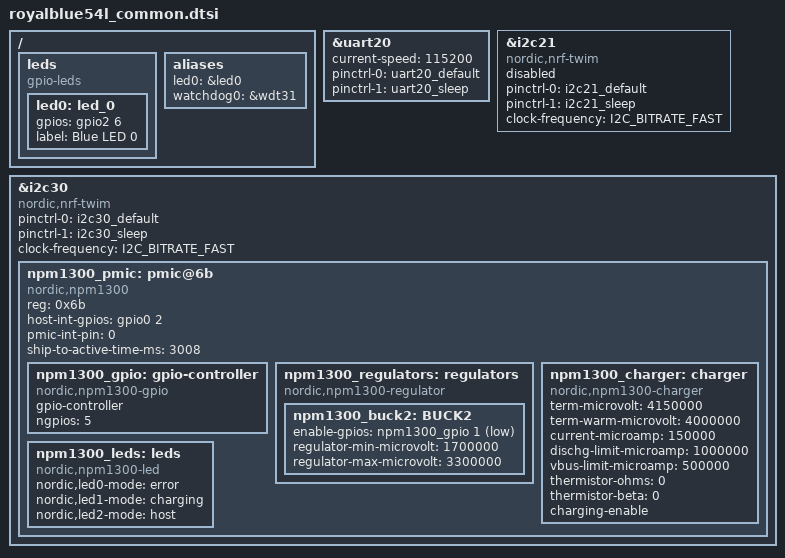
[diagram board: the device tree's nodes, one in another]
/*
 * Copyright (c) 2024 Nordic Semiconductor ASA
 *
 * SPDX-License-Identifier: Apache-2.0
 */

#include "royalblue54l_nrf54l15-pinctrl.dtsi"

/ {
	leds {
		compatible = "gpio-leds";
		led0: led_0 {
			gpios = <&gpio2 6 GPIO_ACTIVE_HIGH>;
			label = "Blue LED 0";
		};
	};

	aliases {
		led0 = &led0;
		watchdog0 = &wdt31;
	};
};

&uart20 {
	current-speed = <115200>;
	pinctrl-0 = <&uart20_default>;
	pinctrl-1 = <&uart20_sleep>;
	pinctrl-names = "default", "sleep";
};

&i2c21 {
	compatible = "nordic,nrf-twim";
	status = "disabled";
	pinctrl-0 = <&i2c21_default>;
	pinctrl-1 = <&i2c21_sleep>;
	pinctrl-names = "default", "sleep";
	clock-frequency = <I2C_BITRATE_FAST>;
};

&i2c30 {
	compatible = "nordic,nrf-twim";
	status = "okay";
	pinctrl-0 = <&i2c30_default>;
	pinctrl-1 = <&i2c30_sleep>;
	pinctrl-names = "default", "sleep";
	clock-frequency = <I2C_BITRATE_FAST>;

	npm1300_pmic: pmic@6b {
		compatible = "nordic,npm1300";
		reg = <0x6b>;
		host-int-gpios = <&gpio0 2 GPIO_ACTIVE_HIGH>;
		pmic-int-pin = <0>;
		ship-to-active-time-ms = <3008>;

		npm1300_gpio: gpio-controller {
			compatible = "nordic,npm1300-gpio";
			gpio-controller;
			#gpio-cells = <2>;
			ngpios = <5>;
		};

		npm1300_regulators: regulators {
			compatible = "nordic,npm1300-regulator";
			npm1300_buck2: BUCK2 {
				enable-gpios = <&npm1300_gpio 1 GPIO_ACTIVE_LOW>;
				regulator-min-microvolt = <1700000>;
				regulator-max-microvolt = <3300000>;
			};
		};

		npm1300_charger: charger {
			compatible = "nordic,npm1300-charger";
			term-microvolt = <4150000>;
			term-warm-microvolt = <4000000>;
			current-microamp = <150000>;
			dischg-limit-microamp = <1000000>;
			vbus-limit-microamp = <500000>;
			thermistor-ohms = <0>;
			thermistor-beta = <0>;
			charging-enable;
		};

		npm1300_leds: leds {
			compatible = "nordic,npm1300-led";
			nordic,led0-mode = "error";
			nordic,led1-mode = "charging";
			nordic,led2-mode = "host";
		};
	};
};
